VERSION "HSCAN1"

NS_ :

BS_:

BU_: BMS HVDCDC Gateway HCU Diagnostics Stability_Control_System Sensing_Diagnostic_Module vector__xxx

BO_ 663 BMS_HSC1_FrP02: 8 BMS
 SG_ BMSMainRelaySts_h1HSC1 : 54|2@0+ (1,0) [0|3] ""  HVDCDC

BO_ 667 BMS_HSC1_FrP07: 8 BMS
 SG_ BMSChrgrPlugCnctnIO_h1HSC1 : 6|1@0+ (1,0) [0|1] ""  Gateway
 SG_ BMSChrgStsIO_h1HSC1 : 7|1@0+ (1,0) [0|1] ""  Gateway

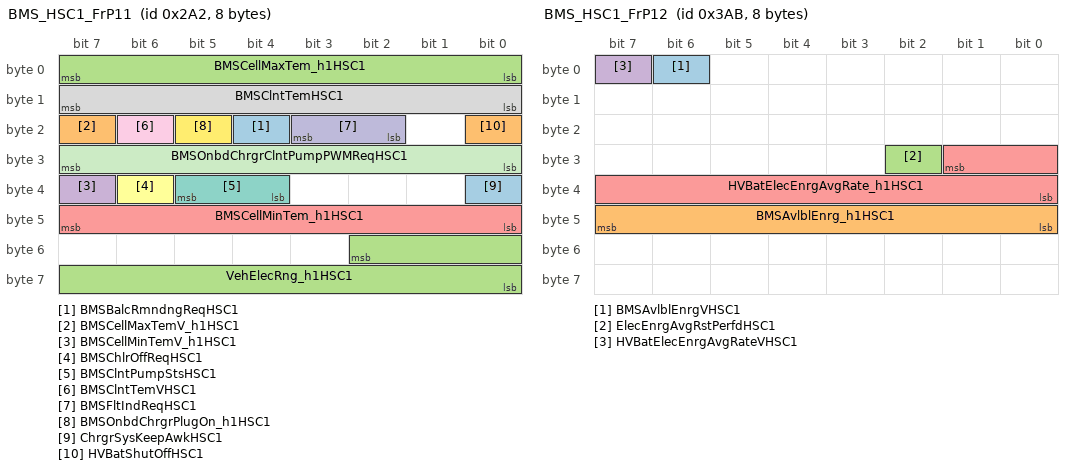
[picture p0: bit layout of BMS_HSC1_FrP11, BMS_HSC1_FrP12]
BO_ 674 BMS_HSC1_FrP11: 8 BMS
 SG_ BMSBalcRmndngReqHSC1 : 20|1@0+ (1,0) [0|1] ""  Gateway
 SG_ BMSCellMaxTemV_h1HSC1 : 23|1@0+ (1,0) [0|1] ""  Gateway,HCU
 SG_ BMSCellMaxTem_h1HSC1 : 7|8@0+ (0.5,-40) [-40|87.5] "DegC"  Gateway,HCU
 SG_ BMSCellMinTemV_h1HSC1 : 39|1@0+ (1,0) [0|1] ""  HCU
 SG_ BMSCellMinTem_h1HSC1 : 47|8@0+ (0.5,-40) [-40|87.5] "Deg C"  HCU
 SG_ BMSChlrOffReqHSC1 : 38|1@0+ (1,0) [0|1] ""  Gateway,HCU
 SG_ BMSClntPumpStsHSC1 : 37|2@0+ (1,0) [0|3] ""  Gateway
 SG_ BMSClntTemHSC1 : 15|8@0+ (0.5,-40) [-40|87.5] "degC"  Gateway,HCU
 SG_ BMSClntTemVHSC1 : 22|1@0+ (1,0) [0|1] ""  Gateway,HCU
 SG_ BMSFltIndReqHSC1 : 19|2@0+ (1,0) [0|3] ""  Gateway
 SG_ BMSOnbdChrgrClntPumpPWMReqHSC1 : 31|8@0+ (0.4,0) [0|102] "%"  HCU
 SG_ BMSOnbdChrgrPlugOn_h1HSC1 : 21|1@0+ (1,0) [0|1] ""  Gateway,HCU
 SG_ ChrgrSysKeepAwkHSC1 : 32|1@0+ (1,0) [0|1] ""  HVDCDC
 SG_ HVBatShutOffHSC1 : 16|1@0+ (1,0) [0|1] ""  Gateway
 SG_ VehElecRng_h1HSC1 : 50|11@0+ (1,0) [0|2047] "km"  Gateway

BO_ 939 BMS_HSC1_FrP12: 8 BMS
 SG_ BMSAvlblEnrgVHSC1 : 6|1@0+ (1,0) [0|1] ""  Gateway,HCU
 SG_ BMSAvlblEnrg_h1HSC1 : 47|8@0+ (0.1,0) [0|25.5] "kWh"  Gateway,HCU
 SG_ ElecEnrgAvgRstPerfdHSC1 : 26|1@0+ (1,0) [0|1] ""  Gateway
 SG_ HVBatElecEnrgAvgRateVHSC1 : 7|1@0+ (1,0) [0|1] ""  Gateway
 SG_ HVBatElecEnrgAvgRate_h1HSC1 : 25|10@0+ (0.1,-20) [-20|82.3] ""  Gateway

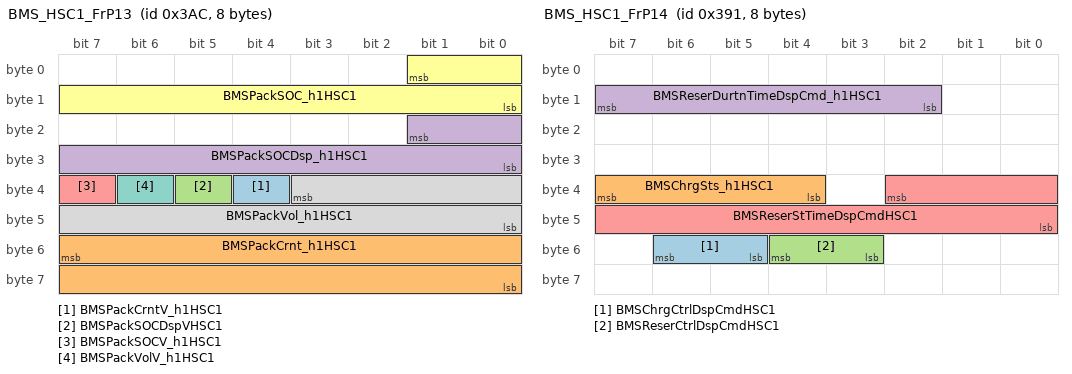
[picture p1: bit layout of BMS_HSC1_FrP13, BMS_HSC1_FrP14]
BO_ 940 BMS_HSC1_FrP13: 8 BMS
 SG_ BMSPackCrntV_h1HSC1 : 36|1@0+ (1,0) [0|1] ""  Gateway
 SG_ BMSPackCrnt_h1HSC1 : 55|16@0+ (0.025,-1000) [-1000|638.375] "A"  Gateway
 SG_ BMSPackSOCDspVHSC1 : 37|1@0+ (1,0) [0|1] ""  Gateway
 SG_ BMSPackSOCDsp_h1HSC1 : 17|10@0+ (0.1,0) [0|102.3] ""  Gateway
 SG_ BMSPackSOCV_h1HSC1 : 39|1@0+ (1,0) [0|1] ""  vector__xxx
 SG_ BMSPackSOC_h1HSC1 : 1|10@0+ (0.1,0) [0|102.3] "%"  vector__xxx
 SG_ BMSPackVolV_h1HSC1 : 38|1@0+ (1,0) [0|1] ""  HVDCDC,Gateway
 SG_ BMSPackVol_h1HSC1 : 35|12@0+ (0.25,0) [0|1023.75] "V"  HVDCDC,Gateway

BO_ 913 BMS_HSC1_FrP14: 8 BMS
 SG_ BMSChrgCtrlDspCmdHSC1 : 54|2@0+ (1,0) [0|3] ""  Gateway
 SG_ BMSChrgSts_h1HSC1 : 39|4@0+ (1,0) [0|15] ""  Gateway
 SG_ BMSReserCtrlDspCmdHSC1 : 52|2@0+ (1,0) [0|3] ""  Gateway
 SG_ BMSReserDurtnTimeDspCmd_h1HSC1 : 15|6@0+ (0.5,0) [0|20] ""  Gateway
 SG_ BMSReserStTimeDspCmdHSC1 : 34|11@0+ (1,0) [0|2047] ""  Gateway

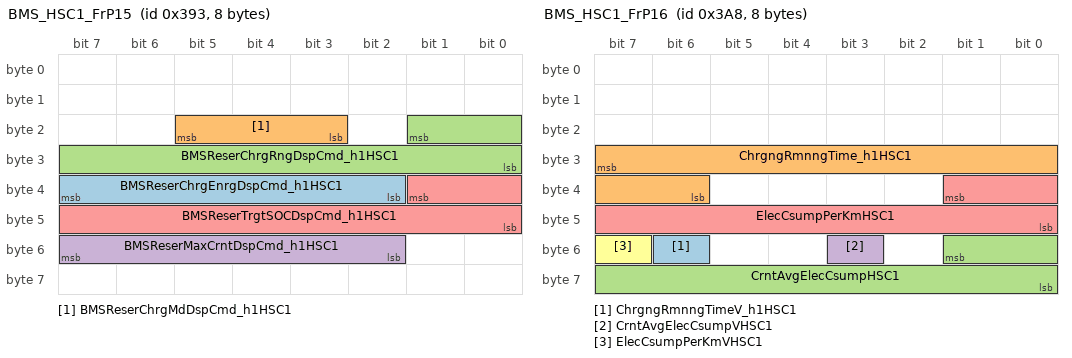
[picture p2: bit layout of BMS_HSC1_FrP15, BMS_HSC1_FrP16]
BO_ 915 BMS_HSC1_FrP15: 8 BMS
 SG_ BMSReserChrgEnrgDspCmd_h1HSC1 : 39|6@0+ (1,0) [0|63] ""  Gateway
 SG_ BMSReserChrgMdDspCmd_h1HSC1 : 21|3@0+ (1,0) [0|7] ""  Gateway
 SG_ BMSReserChrgRngDspCmd_h1HSC1 : 17|10@0+ (1,0) [0|1023] ""  Gateway
 SG_ BMSReserMaxCrntDspCmd_h1HSC1 : 55|6@0+ (1,0) [0|32] ""  Gateway
 SG_ BMSReserTrgtSOCDspCmd_h1HSC1 : 33|10@0+ (0.1,0) [0|102.3] ""  Gateway

BO_ 936 BMS_HSC1_FrP16: 8 BMS
 SG_ ChrgngRmnngTimeV_h1HSC1 : 54|1@0+ (1,0) [0|1] ""  Gateway
 SG_ ChrgngRmnngTime_h1HSC1 : 31|10@0+ (1,0) [0|1023] "minute"  Gateway
 SG_ CrntAvgElecCsumpHSC1 : 49|10@0+ (0.1,-20) [-20|82.3] "kwh/100km"  Gateway
 SG_ CrntAvgElecCsumpVHSC1 : 51|1@0+ (1,0) [0|1] ""  Gateway
 SG_ ElecCsumpPerKmHSC1 : 33|10@0+ (0.1,-20) [-20|82.3] "kwh/100km"  Gateway
 SG_ ElecCsumpPerKmVHSC1 : 55|1@0+ (1,0) [0|1] ""  Gateway

BO_ 1803 DIAG_DTCInfo_BMS: 7 BMS
 SG_ DTCInfomationBMSHSC1 : 7|56@0+ (1,0) [0|0] ""  Gateway

BO_ 1929 DIAG_PhysResp_BMS: 8 BMS
 SG_ DiagnosticRespBMS : 7|64@0+ (1,0) [0|0] ""  Diagnostics

BO_ 2015 DIAG_FuncReq_HSC1: 8 Diagnostics
 SG_ DiagnosticFuncAddrReq : 7|64@0+ (1,0) [0|0] ""  BMS

BO_ 1921 DIAG_PhysReq_BMS: 8 Diagnostics
 SG_ DiagnosticReqBMS : 7|64@0+ (1,0) [0|0] ""  BMS

BO_ 868 GW_HSC1_AC_FrP03: 8 Gateway
 SG_ ACComprReqHSC1 : 17|2@0+ (1,0) [0|3] ""  BMS
 SG_ HVBatCoolngSysEnbdHSC1 : 55|1@0+ (1,0) [0|1] ""  BMS

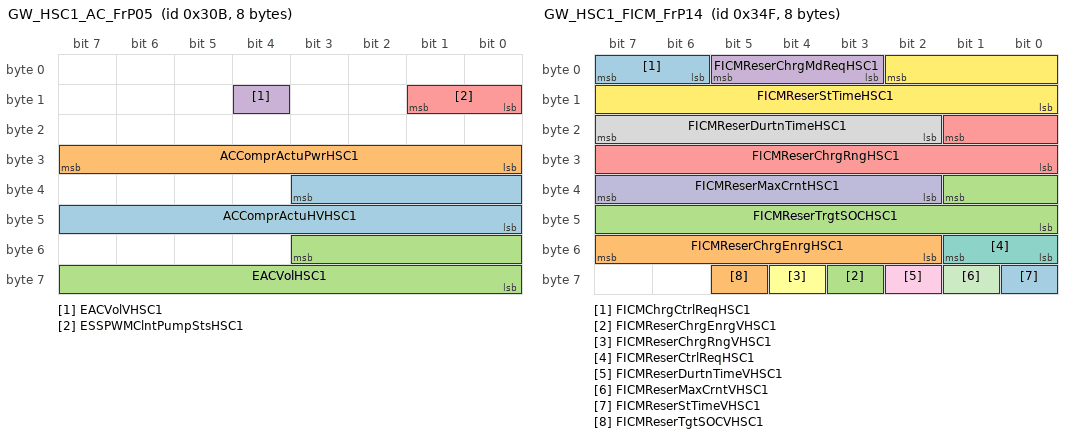
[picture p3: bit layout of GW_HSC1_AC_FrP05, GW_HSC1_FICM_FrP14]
BO_ 779 GW_HSC1_AC_FrP05: 8 Gateway
 SG_ ACComprActuHVHSC1 : 35|12@0+ (0.25,0) [0|1023.25] ""  BMS
 SG_ ACComprActuPwrHSC1 : 31|8@0+ (0.03,0) [0|7.65] "Kw"  BMS
 SG_ EACVolHSC1 : 51|12@0+ (0.25,0) [0|1023.75] ""  BMS
 SG_ EACVolVHSC1 : 12|1@0+ (1,0) [0|1] ""  BMS
 SG_ ESSPWMClntPumpStsHSC1 : 9|2@0+ (1,0) [0|3] ""  BMS

BO_ 883 GW_HSC1_AC_FrP06: 8 Gateway
 SG_ ACHtrPwrHSC1 : 15|8@0+ (0.03,0) [0|7.65] "Unit:KW"  BMS

BO_ 1130 GW_HSC1_BCM_FrP04: 8 Gateway
 SG_ VehLckngStaHSC1 : 22|3@0+ (1,0) [0|7] ""  BMS

BO_ 540 GW_HSC1_BCM_FrP06: 8 Gateway
 SG_ RVSReqHSC1 : 34|1@0+ (1,0) [0|1] ""  BMS

BO_ 498 GW_HSC1_BCM_FrP07: 2 Gateway
 SG_ SysBPMHSC1 : 5|2@0+ (1,0) [0|3] ""  BMS
 SG_ SysBPMEnbdHSC1 : 6|1@0+ (1,0) [0|1] ""  BMS

BO_ 886 GW_HSC1_FICM_FrP02: 8 Gateway
 SG_ RstrFctryDeftsReqHSC1 : 56|1@0+ (1,0) [0|1] ""  BMS

BO_ 847 GW_HSC1_FICM_FrP14: 8 Gateway
 SG_ FICMChrgCtrlReqHSC1 : 7|2@0+ (1,0) [0|3] ""  BMS
 SG_ FICMReserChrgEnrgHSC1 : 55|6@0+ (1,0) [0|63] ""  BMS
 SG_ FICMReserChrgEnrgVHSC1 : 59|1@0+ (1,0) [0|1] ""  BMS
 SG_ FICMReserChrgMdReqHSC1 : 5|3@0+ (1,0) [0|7] ""  BMS
 SG_ FICMReserChrgRngHSC1 : 17|10@0+ (1,0) [0|1023] ""  BMS
 SG_ FICMReserChrgRngVHSC1 : 60|1@0+ (1,0) [0|1] ""  BMS
 SG_ FICMReserCtrlReqHSC1 : 49|2@0+ (1,0) [0|3] ""  BMS
 SG_ FICMReserDurtnTimeHSC1 : 23|6@0+ (1,0) [0|63] ""  BMS
 SG_ FICMReserDurtnTimeVHSC1 : 58|1@0+ (1,0) [0|1] ""  BMS
 SG_ FICMReserMaxCrntHSC1 : 39|6@0+ (1,0) [0|32] ""  BMS
 SG_ FICMReserMaxCrntVHSC1 : 57|1@0+ (1,0) [0|1] ""  BMS
 SG_ FICMReserStTimeHSC1 : 2|11@0+ (1,0) [0|2047] ""  BMS
 SG_ FICMReserStTimeVHSC1 : 56|1@0+ (1,0) [0|1] ""  BMS
 SG_ FICMReserTgtSOCVHSC1 : 61|1@0+ (1,0) [0|1] ""  BMS
 SG_ FICMReserTrgtSOCHSC1 : 33|10@0+ (0.1,0) [0|102.3] ""  BMS

BO_ 361 GW_HSC1_FrP00: 6 Gateway
 SG_ BCMAvlbly_h1HSC1 : 31|1@0+ (1,0) [0|1] ""  BMS
 SG_ SCSAvlbly_h1HSC1 : 4|1@0+ (1,0) [0|1] ""  BMS

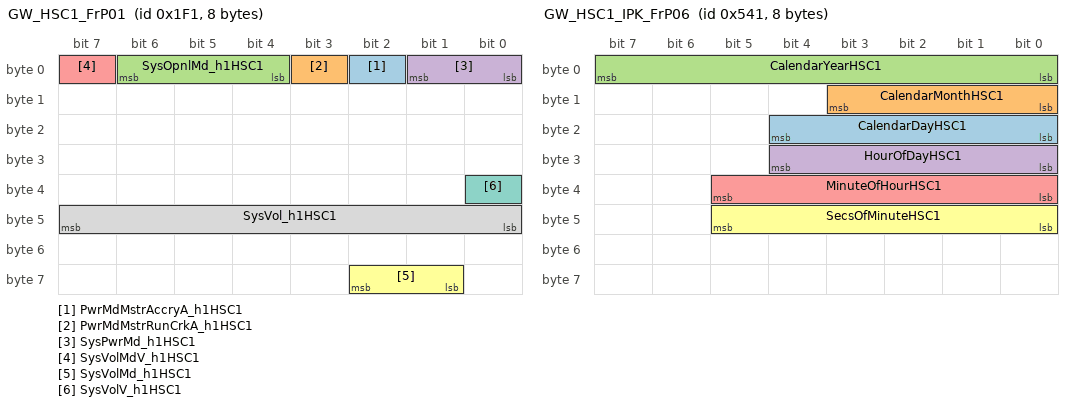
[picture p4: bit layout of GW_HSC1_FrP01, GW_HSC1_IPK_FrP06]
BO_ 497 GW_HSC1_FrP01: 8 Gateway
 SG_ PwrMdMstrAccryA_h1HSC1 : 2|1@0+ (1,0) [0|1] ""  BMS
 SG_ PwrMdMstrRunCrkA_h1HSC1 : 3|1@0+ (1,0) [0|1] ""  BMS
 SG_ SysOpnlMd_h1HSC1 : 6|3@0+ (1,0) [0|7] ""  BMS
 SG_ SysPwrMd_h1HSC1 : 1|2@0+ (1,0) [0|3] ""  BMS
 SG_ SysVolMdV_h1HSC1 : 7|1@0+ (1,0) [0|1] ""  BMS
 SG_ SysVolMd_h1HSC1 : 58|2@0+ (1,0) [0|3] ""  BMS
 SG_ SysVolV_h1HSC1 : 32|1@0+ (1,0) [0|1] ""  BMS
 SG_ SysVol_h1HSC1 : 47|8@0+ (0.1,3) [3|28.5] "V"  BMS

BO_ 1344 GW_HSC1_FrP07: 8 Gateway
 SG_ VehOdoV_h1HSC1 : 31|1@0+ (1,0) [0|1] ""  BMS
 SG_ VehOdo_h1HSC1 : 7|24@0+ (1,0) [0|16777200] ""  BMS

BO_ 1009 GW_HSC1_FrP10: 8 Gateway
 SG_ OtsdAirTemCrValV_h1HSC1 : 48|1@0+ (1,0) [0|1] ""  BMS
 SG_ OtsdAirTemCrVal_h1HSC1 : 63|8@0+ (0.5,-40) [-40|87.5] "deg C"  BMS

BO_ 1345 GW_HSC1_IPK_FrP06: 8 Gateway
 SG_ CalendarDayHSC1 : 20|5@0+ (1,0) [0|31] ""  BMS
 SG_ CalendarMonthHSC1 : 11|4@0+ (1,0) [0|15] ""  BMS
 SG_ CalendarYearHSC1 : 7|8@0+ (1,2000) [2000|2255] ""  BMS
 SG_ HourOfDayHSC1 : 28|5@0+ (1,0) [0|23] ""  BMS
 SG_ MinuteOfHourHSC1 : 37|6@0+ (1,0) [0|59] ""  BMS
 SG_ SecsOfMinuteHSC1 : 45|6@0+ (1,0) [0|59] ""  BMS

BO_ 835 GW_HSC1_IPK_FrP10: 8 Gateway
 SG_ ElecEnrgAvgRstReqHSC1 : 13|2@0+ (1,0) [0|3] ""  BMS

BO_ 175 HCU_HSC1_FrP00: 8 HCU
 SG_ EPTStCmdOnHSC1 : 17|1@0+ (1,0) [0|1] ""  BMS

BO_ 406 HCU_HSC1_FrP01: 8 HCU
 SG_ EPTRdyHSC1 : 38|1@0+ (1,0) [0|1] ""  BMS

BO_ 907 HCU_HSC1_FrP07: 8 HCU
 SG_ EPTEDUClntTemHSC1 : 47|8@0+ (1,-40) [-40|215] "DegC"  BMS
 SG_ EPTEDUClntTemVHSC1 : 13|1@0+ (1,0) [0|1] ""  BMS

BO_ 780 HCU_HSC1_FrP10: 8 HCU
 SG_ EPTEDUClntPumpStsHSC1 : 58|3@0+ (1,0) [0|7] ""  BMS

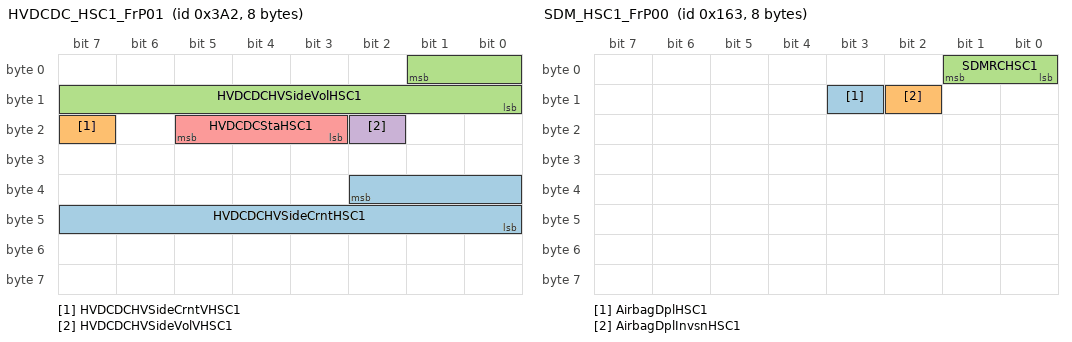
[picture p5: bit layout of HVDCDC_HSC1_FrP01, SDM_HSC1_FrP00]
BO_ 930 HVDCDC_HSC1_FrP01: 8 HVDCDC
 SG_ HVDCDCHVSideCrntHSC1 : 34|11@0+ (1,-1023) [-1023|1024] "A"  BMS
 SG_ HVDCDCHVSideCrntVHSC1 : 23|1@0+ (1,0) [0|1] ""  BMS
 SG_ HVDCDCHVSideVolHSC1 : 1|10@0+ (1,0) [0|1023] "V"  BMS
 SG_ HVDCDCHVSideVolVHSC1 : 18|1@0+ (1,0) [0|1] ""  BMS
 SG_ HVDCDCStaHSC1 : 21|3@0+ (1,0) [0|7] ""  BMS

BO_ 851 SCS_HSC1_FrP15: 8 Stability_Control_System
 SG_ VehSpdAvgDrvnV_h1HSC1 : 7|1@0+ (1,0) [0|1] ""  BMS
 SG_ VehSpdAvgDrvn_h1HSC1 : 6|15@0+ (0.015625,0) [0|511.984] "km/h"  BMS

BO_ 355 SDM_HSC1_FrP00: 8 Sensing_Diagnostic_Module
 SG_ AirbagDplHSC1 : 11|1@0+ (1,0) [0|1] ""  BMS
 SG_ AirbagDplInvsnHSC1 : 10|1@0+ (1,0) [0|1] ""  BMS
 SG_ SDMRCHSC1 : 1|2@0+ (1,0) [0|3] ""  BMS

CM_ SG_ 663 BMSMainRelaySts_h1HSC1 "Battery Management System Main Relay Status";
CM_ SG_ 667 BMSChrgrPlugCnctnIO_h1HSC1 "Battery Management System Charger Plug Connection Indication On";
CM_ SG_ 667 BMSChrgStsIO_h1HSC1 "Battery Management System Charge Status Indication On";
CM_ SG_ 674 BMSBalcRmndngReqHSC1 "Battery Management System Balance Reminding Request
";
CM_ SG_ 674 BMSCellMaxTemV_h1HSC1 "Battery Management System Cell Maximum Temperature Validity
";
CM_ SG_ 674 BMSCellMaxTem_h1HSC1 "Battery Management System Cell Maximum Temperature
";
CM_ SG_ 674 BMSCellMinTemV_h1HSC1 "Battery Management System Cell Minimum Temperature Validity";
CM_ SG_ 674 BMSCellMinTem_h1HSC1 "Battery Management System Cell Minimum Temperature";
CM_ SG_ 674 BMSChlrOffReqHSC1 "Battery Management System Chiller Off Request";
CM_ SG_ 674 BMSClntPumpStsHSC1 "Battery Management System Coolant Pump Status
";
CM_ SG_ 674 BMSClntTemHSC1 "Battery Management System Coolant Temperature";
CM_ SG_ 674 BMSClntTemVHSC1 "Battery Management System Coolant Temperature Validity";
CM_ SG_ 674 BMSFltIndReqHSC1 "Battery Management System Fault Indication Request
";
CM_ SG_ 674 BMSOnbdChrgrClntPumpPWMReqHSC1 "Battery Management System Onboard Charger Coolant Pump Pulse Width Modulation Request";
CM_ SG_ 674 BMSOnbdChrgrPlugOn_h1HSC1 "Battery Management System Onboard Charger Plug On";
CM_ SG_ 674 ChrgrSysKeepAwkHSC1 "Charger System Keep Awake";
CM_ SG_ 674 HVBatShutOffHSC1 "High Voltage Battery Shut Off";
CM_ SG_ 674 VehElecRng_h1HSC1 "Vehicle Electric Range";
CM_ SG_ 939 BMSAvlblEnrgVHSC1 "Battery Management System Available Energy Validity";
CM_ SG_ 939 BMSAvlblEnrg_h1HSC1 "Battery Management System Available Energy";
CM_ SG_ 939 ElecEnrgAvgRstPerfdHSC1 "Electric Energy Average Reset Performed";
CM_ SG_ 939 HVBatElecEnrgAvgRateVHSC1 "High Voltage Battery Electric Energy Average Rate Validity";
CM_ SG_ 939 HVBatElecEnrgAvgRate_h1HSC1 "High Voltage Battery Electric Energy Average Rate";
CM_ SG_ 940 BMSPackCrntV_h1HSC1 "Battery Management System Pack Current Validity";
CM_ SG_ 940 BMSPackCrnt_h1HSC1 "Battery Management System Pack Current";
CM_ SG_ 940 BMSPackSOCDspVHSC1 "Battery Management System Pack State Of Charge Display Validity";
CM_ SG_ 940 BMSPackSOCDsp_h1HSC1 "SOC displayed for customer";
CM_ SG_ 940 BMSPackSOCV_h1HSC1 "Battery Management System Pack State Of Charge Validity
";
CM_ SG_ 940 BMSPackSOC_h1HSC1 "Battery Management System Pack State Of Charge
";
CM_ SG_ 940 BMSPackVolV_h1HSC1 "Battery Management System Pack Voltage Validity";
CM_ SG_ 940 BMSPackVol_h1HSC1 "Battery Management System Pack Voltage";
CM_ SG_ 913 BMSChrgCtrlDspCmdHSC1 "Battery Management System Charge Control Display Command";
CM_ SG_ 913 BMSChrgSts_h1HSC1 "Battery Management System Charge Status";
CM_ SG_ 913 BMSReserCtrlDspCmdHSC1 "Battery Management System Reservation Control Display Command";
CM_ SG_ 913 BMSReserDurtnTimeDspCmd_h1HSC1 "Battery Management System Reservation Duration Time Display Command";
CM_ SG_ 913 BMSReserStTimeDspCmdHSC1 "Battery Management System Reservation Start Time Display Command";
CM_ SG_ 915 BMSReserChrgEnrgDspCmd_h1HSC1 "Battery Management System Reservation Charge Energy Display Command";
CM_ SG_ 915 BMSReserChrgMdDspCmd_h1HSC1 "Battery Management System Reservation Charge Mode Display Command";
CM_ SG_ 915 BMSReserChrgRngDspCmd_h1HSC1 "Battery Management System Reservation Charge Range Display Command";
CM_ SG_ 915 BMSReserMaxCrntDspCmd_h1HSC1 "Battery Management System Reservation Maximun Current Display Command";
CM_ SG_ 915 BMSReserTrgtSOCDspCmd_h1HSC1 "Battery Management System Reservaion Target Soc Display Command";
CM_ SG_ 936 ChrgngRmnngTimeV_h1HSC1 "Charging Remaining Time Validity";
CM_ SG_ 936 ChrgngRmnngTime_h1HSC1 "Charging Remaining Time";
CM_ SG_ 936 CrntAvgElecCsumpHSC1 "Current Average Electric Consumption";
CM_ SG_ 936 CrntAvgElecCsumpVHSC1 "Current Average Electric Consumption Validity";
CM_ SG_ 936 ElecCsumpPerKmHSC1 "Electric Consumption Per Kilometer";
CM_ SG_ 936 ElecCsumpPerKmVHSC1 "Electric Consumption Per Kilometer Validity";
CM_ SG_ 1803 DTCInfomationBMSHSC1 "DTC Infomation of BMS

The length of DTC information signal is 7 bytes.
Byte 0 is MSB (most significant byte), and Byte 6 is LSB (least significant byte).
For each byte, Bit 7 is msb (most significant bit), and Bit 0 is lsb (least significant bit).

Byte 0:
Bit (7-4): DTC Serious Level
Bit (3-0): Reserved

Byte 1:
Bit (7-0): Reserved

Byte 2:
Bit (7-0): DTCHighByte

Byte 3:
Bit (7-0): DTCLowByte

Byte 4:
Bit (7-0): DTCFailureTypeByte

Byte 5:
Bit 7: warningIndicatorRequested
Bit 6: testNotCompletedThisOperationCycle
Bit 5: testFailedSinceLastClear
Bit 4: testNotCompletedSinceLastClear
Bit 3: confirmedDTC
Bit 2: pendingDTC
Bit 1: testFailedThisOperationCycle
Bit 0: testFailed

Byte 6:
Bit (7-0): DTC Type

For more detail, please refer to SMTC 2 800 004.
";
CM_ SG_ 1929 DiagnosticRespBMS "Diagnostic response from BMS";
CM_ SG_ 2015 DiagnosticFuncAddrReq "Diagnostic functional address request";
CM_ SG_ 1921 DiagnosticReqBMS "Diagnostic request to BMS";
CM_ SG_ 868 ACComprReqHSC1 "Air Conditioning Compressor Request";
CM_ SG_ 868 HVBatCoolngSysEnbdHSC1 "High Voltage Battery Cooling System Enabled
";
CM_ SG_ 779 ACComprActuHVHSC1 "Air Conditioning Compressor Actual High Voltage
";
CM_ SG_ 779 ACComprActuPwrHSC1 "Air Conditioning Compressor Actual Power
";
CM_ SG_ 779 EACVolHSC1 "Electric Air Conditioning Compressor Voltage
";
CM_ SG_ 779 EACVolVHSC1 "Electric Air Conditioning Compressor Voltage Validity
";
CM_ SG_ 779 ESSPWMClntPumpStsHSC1 "Energy Storage System Pulse Width Modulation Coolant Pump Status";
CM_ SG_ 1130 VehLckngStaHSC1 "Vehicle Locking State";
CM_ SG_ 540 RVSReqHSC1 "Remote Vehicle Start Request";
CM_ SG_ 498 SysBPMHSC1 "System Backup Power Mode";
CM_ SG_ 498 SysBPMEnbdHSC1 "System Backup Power Mode Enabled";
CM_ SG_ 886 RstrFctryDeftsReqHSC1 "Restore Factory Defaults Request";
CM_ SG_ 847 FICMChrgCtrlReqHSC1 "Front Infotainment Control Module Charge Control Request";
CM_ SG_ 847 FICMReserChrgEnrgHSC1 "Front Infotainment Control Module Reservation Charge Energy";
CM_ SG_ 847 FICMReserChrgEnrgVHSC1 "Front Infotainment Control Module Reservation Charge Energy Validity";
CM_ SG_ 847 FICMReserChrgMdReqHSC1 "Front Infotainment Control Module Reservation Charge Mode Request";
CM_ SG_ 847 FICMReserChrgRngHSC1 "Front Infotainment Control Module Reservation Charge Range";
CM_ SG_ 847 FICMReserChrgRngVHSC1 "Front Infotainment Control Module Reservation Charge Range Validity";
CM_ SG_ 847 FICMReserCtrlReqHSC1 "Front Infotainment Control Module Reservation Control Request";
CM_ SG_ 847 FICMReserDurtnTimeHSC1 "Front Infotainment Control Module Reservation Duration Time";
CM_ SG_ 847 FICMReserDurtnTimeVHSC1 "Front Infotainment Control Module Reservation Duration Time Validity";
CM_ SG_ 847 FICMReserMaxCrntHSC1 "Front Infotainment Control Module Reservation Maximun Current Request";
CM_ SG_ 847 FICMReserMaxCrntVHSC1 "Front Infotainment Control Module Reservation Maximun Current Request Validity";
CM_ SG_ 847 FICMReserStTimeHSC1 "Front Infotainment Control Module Reservation Start Time";
CM_ SG_ 847 FICMReserStTimeVHSC1 "Front Infotainment Control Module Reservation Start Time Validity";
CM_ SG_ 847 FICMReserTgtSOCVHSC1 "Front Infotainment Control Module Reservation Target Soc Validity";
CM_ SG_ 847 FICMReserTrgtSOCHSC1 "Front Infotainment Control Module Reservation Target Soc";
CM_ SG_ 361 BCMAvlbly_h1HSC1 "BCM Available

Detect if specific ECU is available according to node missing strategy by gateway ECU.
";
CM_ SG_ 361 SCSAvlbly_h1HSC1 "SCS Available

Detect if specific ECU is available according to node missing strategy by gateway ECU.

";
CM_ SG_ 497 PwrMdMstrAccryA_h1HSC1 "Power Mode Master Accessory Terminal Status";
CM_ SG_ 497 PwrMdMstrRunCrkA_h1HSC1 "Power Mode Master Run Crank Terminal Status";
CM_ SG_ 497 SysOpnlMd_h1HSC1 "System Operational Mode";
CM_ SG_ 497 SysPwrMd_h1HSC1 "System Power Mode";
CM_ SG_ 497 SysVolMdV_h1HSC1 "System Voltage Mode Validity ";
CM_ SG_ 497 SysVolMd_h1HSC1 "System Voltage Mode ";
CM_ SG_ 497 SysVolV_h1HSC1 "Battery Voltage Validity";
CM_ SG_ 497 SysVol_h1HSC1 "Battery Voltage";
CM_ SG_ 1344 VehOdoV_h1HSC1 "Vehicle Odometer Validity";
CM_ SG_ 1344 VehOdo_h1HSC1 "Vehicle Odometer";
CM_ SG_ 1009 OtsdAirTemCrValV_h1HSC1 "Outside Air Temperature Corrected Value Validity";
CM_ SG_ 1009 OtsdAirTemCrVal_h1HSC1 "Outside Air Temperature Corrected Value";
CM_ SG_ 1345 CalendarDayHSC1 "current day info.";
CM_ SG_ 1345 CalendarMonthHSC1 "current month info.";
CM_ SG_ 1345 CalendarYearHSC1 "current year info";
CM_ SG_ 1345 HourOfDayHSC1 "Hour Of Day.
current Hour info.";
CM_ SG_ 1345 MinuteOfHourHSC1 "Minute Of Hour.
current Minute info.";
CM_ SG_ 1345 SecsOfMinuteHSC1 "Seconds Of Minute
current Second info.";
CM_ SG_ 835 ElecEnrgAvgRstReqHSC1 "Electric Energy Average Reset Request";
CM_ SG_ 175 EPTStCmdOnHSC1 "Electric Powertrain Start Command On";
CM_ SG_ 406 EPTRdyHSC1 "Electric Powertrain Ready";
CM_ SG_ 907 EPTEDUClntTemHSC1 "Electric Powertrain Electric Drive Unit Coolant Temperature
";
CM_ SG_ 907 EPTEDUClntTemVHSC1 "Electric Powertrain Electric Drive Unit Coolant Temperature Validity
";
CM_ SG_ 780 EPTEDUClntPumpStsHSC1 "Electric Powertrain Electric Drive Unit Coolant Pump StatusElectric Powertrain Electric Drive Unit Coolant Pump Status";
CM_ SG_ 930 HVDCDCHVSideCrntHSC1 "High Voltage Direct Current Direct Current High Voltage Side Current";
CM_ SG_ 930 HVDCDCHVSideVolHSC1 "High Voltage Direct Current Direct Current High Voltage Side Voltage";
CM_ SG_ 930 HVDCDCHVSideVolVHSC1 "High Voltage Direct Current Direct Current High Voltage Side Voltage Validity";
CM_ SG_ 930 HVDCDCStaHSC1 "High Voltage Direct Current Direct Current State";
CM_ SG_ 851 VehSpdAvgDrvnV_h1HSC1 "Vehicle Speed Average Driven Validity";
CM_ SG_ 851 VehSpdAvgDrvn_h1HSC1 "Vehicle Speed Average Driven";
CM_ SG_ 355 AirbagDplHSC1 "Airbag Deployed";
CM_ SG_ 355 AirbagDplInvsnHSC1 "Airbag Deployed Inversion";
CM_ SG_ 355 SDMRCHSC1 "Sensing Diagnostic Module Rolling Count
";
BA_DEF_  "BaudRate" FLOAT 1000 1000000;
BA_DEF_ BO_  "GenMsgSendType" ENUM  "cyclic","Spontaneous","cyclicIfActive","spontaneousWithDelay","Immediate";
BA_DEF_ BO_  "GenMsgCycleTime" FLOAT 0 300000;
BA_DEF_ BO_  "GenMsgDelayTime" FLOAT 0 300000;
BA_DEF_ SG_  "GenSigStartValue" INT -9.22337203685478E+018 1.84467440737096E+019;
BA_DEF_ SG_  "GenSigMaxAge" FLOAT 0 300000;
BA_DEF_ SG_  "GenSigPubLatency" INT 0 200;
BA_DEF_ SG_  "GenSigWriteInterval" INT 0 5000;
BA_DEF_DEF_  "BaudRate" 1000;
BA_DEF_DEF_  "GenMsgSendType" "";
BA_DEF_DEF_  "GenMsgCycleTime" 0;
BA_DEF_DEF_  "GenMsgDelayTime" 0;
BA_DEF_DEF_  "GenSigStartValue" 0;
BA_DEF_DEF_  "GenSigMaxAge" 0;
BA_DEF_DEF_  "GenSigPubLatency" 0;
BA_DEF_DEF_  "GenSigWriteInterval" 0;
BA_ "BaudRate" 500000;
BA_ "GenMsgSendType" BO_ 663 0;
BA_ "GenMsgCycleTime" BO_ 663 50;
BA_ "GenMsgSendType" BO_ 667 0;
BA_ "GenMsgCycleTime" BO_ 667 50;
BA_ "GenMsgSendType" BO_ 674 0;
BA_ "GenMsgCycleTime" BO_ 674 100;
BA_ "GenMsgSendType" BO_ 939 0;
BA_ "GenMsgCycleTime" BO_ 939 100;
BA_ "GenMsgSendType" BO_ 940 0;
BA_ "GenMsgCycleTime" BO_ 940 100;
BA_ "GenMsgSendType" BO_ 913 0;
BA_ "GenMsgCycleTime" BO_ 913 100;
BA_ "GenMsgSendType" BO_ 915 0;
BA_ "GenMsgCycleTime" BO_ 915 100;
BA_ "GenMsgSendType" BO_ 936 0;
BA_ "GenMsgCycleTime" BO_ 936 100;
BA_ "GenMsgSendType" BO_ 1803 1;
BA_ "GenMsgSendType" BO_ 1929 4;
BA_ "GenMsgSendType" BO_ 2015 4;
BA_ "GenMsgSendType" BO_ 1921 4;
BA_ "GenMsgSendType" BO_ 868 0;
BA_ "GenMsgCycleTime" BO_ 868 100;
BA_ "GenMsgSendType" BO_ 779 0;
BA_ "GenMsgCycleTime" BO_ 779 100;
BA_ "GenMsgSendType" BO_ 883 0;
BA_ "GenMsgCycleTime" BO_ 883 100;
BA_ "GenMsgSendType" BO_ 1130 0;
BA_ "GenMsgCycleTime" BO_ 1130 50;
BA_ "GenMsgSendType" BO_ 540 0;
BA_ "GenMsgCycleTime" BO_ 540 50;
BA_ "GenMsgSendType" BO_ 498 0;
BA_ "GenMsgCycleTime" BO_ 498 20;
BA_ "GenMsgSendType" BO_ 886 0;
BA_ "GenMsgCycleTime" BO_ 886 100;
BA_ "GenMsgSendType" BO_ 847 0;
BA_ "GenMsgCycleTime" BO_ 847 100;
BA_ "GenMsgSendType" BO_ 361 0;
BA_ "GenMsgCycleTime" BO_ 361 20;
BA_ "GenMsgSendType" BO_ 497 0;
BA_ "GenMsgCycleTime" BO_ 497 20;
BA_ "GenMsgSendType" BO_ 1344 0;
BA_ "GenMsgCycleTime" BO_ 1344 1000;
BA_ "GenMsgSendType" BO_ 1009 0;
BA_ "GenMsgCycleTime" BO_ 1009 250;
BA_ "GenMsgSendType" BO_ 1345 0;
BA_ "GenMsgCycleTime" BO_ 1345 200;
BA_ "GenMsgSendType" BO_ 835 0;
BA_ "GenMsgCycleTime" BO_ 835 100;
BA_ "GenMsgSendType" BO_ 175 0;
BA_ "GenMsgCycleTime" BO_ 175 10;
BA_ "GenMsgSendType" BO_ 406 0;
BA_ "GenMsgCycleTime" BO_ 406 20;
BA_ "GenMsgSendType" BO_ 907 0;
BA_ "GenMsgCycleTime" BO_ 907 100;
BA_ "GenMsgSendType" BO_ 780 0;
BA_ "GenMsgCycleTime" BO_ 780 100;
BA_ "GenMsgSendType" BO_ 930 0;
BA_ "GenMsgCycleTime" BO_ 930 100;
BA_ "GenMsgSendType" BO_ 851 0;
BA_ "GenMsgCycleTime" BO_ 851 100;
BA_ "GenMsgSendType" BO_ 355 0;
BA_ "GenMsgCycleTime" BO_ 355 20;
BA_ "GenSigPubLatency" SG_ 663 BMSMainRelaySts_h1HSC1 10;
BA_ "GenSigMaxAge" SG_ 663 BMSMainRelaySts_h1HSC1 500;
BA_ "GenSigPubLatency" SG_ 667 BMSChrgrPlugCnctnIO_h1HSC1 10;
BA_ "GenSigStartValue" SG_ 667 BMSChrgrPlugCnctnIO_h1HSC1 1;
BA_ "GenSigPubLatency" SG_ 667 BMSChrgStsIO_h1HSC1 10;
BA_ "GenSigStartValue" SG_ 667 BMSChrgStsIO_h1HSC1 1;
BA_ "GenSigPubLatency" SG_ 674 BMSBalcRmndngReqHSC1 10;
BA_ "GenSigPubLatency" SG_ 674 BMSCellMaxTemV_h1HSC1 10;
BA_ "GenSigStartValue" SG_ 674 BMSCellMaxTemV_h1HSC1 1;
BA_ "GenSigMaxAge" SG_ 674 BMSCellMaxTemV_h1HSC1 400;
BA_ "GenSigPubLatency" SG_ 674 BMSCellMaxTem_h1HSC1 10;
BA_ "GenSigStartValue" SG_ 674 BMSCellMaxTem_h1HSC1 255;
BA_ "GenSigMaxAge" SG_ 674 BMSCellMaxTem_h1HSC1 400;
BA_ "GenSigPubLatency" SG_ 674 BMSCellMinTemV_h1HSC1 10;
BA_ "GenSigStartValue" SG_ 674 BMSCellMinTemV_h1HSC1 1;
BA_ "GenSigMaxAge" SG_ 674 BMSCellMinTemV_h1HSC1 300;
BA_ "GenSigPubLatency" SG_ 674 BMSCellMinTem_h1HSC1 10;
BA_ "GenSigStartValue" SG_ 674 BMSCellMinTem_h1HSC1 255;
BA_ "GenSigMaxAge" SG_ 674 BMSCellMinTem_h1HSC1 300;
BA_ "GenSigPubLatency" SG_ 674 BMSChlrOffReqHSC1 10;
BA_ "GenSigMaxAge" SG_ 674 BMSChlrOffReqHSC1 300;
BA_ "GenSigPubLatency" SG_ 674 BMSClntPumpStsHSC1 10;
BA_ "GenSigPubLatency" SG_ 674 BMSClntTemHSC1 10;
BA_ "GenSigStartValue" SG_ 674 BMSClntTemHSC1 255;
BA_ "GenSigMaxAge" SG_ 674 BMSClntTemHSC1 300;
BA_ "GenSigPubLatency" SG_ 674 BMSClntTemVHSC1 10;
BA_ "GenSigStartValue" SG_ 674 BMSClntTemVHSC1 1;
BA_ "GenSigMaxAge" SG_ 674 BMSClntTemVHSC1 300;
BA_ "GenSigPubLatency" SG_ 674 BMSFltIndReqHSC1 10;
BA_ "GenSigPubLatency" SG_ 674 BMSOnbdChrgrClntPumpPWMReqHSC1 10;
BA_ "GenSigMaxAge" SG_ 674 BMSOnbdChrgrClntPumpPWMReqHSC1 400;
BA_ "GenSigPubLatency" SG_ 674 BMSOnbdChrgrPlugOn_h1HSC1 10;
BA_ "GenSigMaxAge" SG_ 674 BMSOnbdChrgrPlugOn_h1HSC1 300;
BA_ "GenSigPubLatency" SG_ 674 ChrgrSysKeepAwkHSC1 10;
BA_ "GenSigMaxAge" SG_ 674 ChrgrSysKeepAwkHSC1 500;
BA_ "GenSigPubLatency" SG_ 674 HVBatShutOffHSC1 10;
BA_ "GenSigStartValue" SG_ 674 HVBatShutOffHSC1 1;
BA_ "GenSigMaxAge" SG_ 674 HVBatShutOffHSC1 500;
BA_ "GenSigPubLatency" SG_ 674 VehElecRng_h1HSC1 10;
BA_ "GenSigStartValue" SG_ 674 VehElecRng_h1HSC1 2046;
BA_ "GenSigPubLatency" SG_ 939 BMSAvlblEnrgVHSC1 10;
BA_ "GenSigMaxAge" SG_ 939 BMSAvlblEnrgVHSC1 300;
BA_ "GenSigPubLatency" SG_ 939 BMSAvlblEnrg_h1HSC1 10;
BA_ "GenSigStartValue" SG_ 939 BMSAvlblEnrg_h1HSC1 255;
BA_ "GenSigMaxAge" SG_ 939 BMSAvlblEnrg_h1HSC1 300;
BA_ "GenSigPubLatency" SG_ 939 ElecEnrgAvgRstPerfdHSC1 10;
BA_ "GenSigPubLatency" SG_ 939 HVBatElecEnrgAvgRateVHSC1 10;
BA_ "GenSigStartValue" SG_ 939 HVBatElecEnrgAvgRateVHSC1 1;
BA_ "GenSigPubLatency" SG_ 939 HVBatElecEnrgAvgRate_h1HSC1 10;
BA_ "GenSigStartValue" SG_ 939 HVBatElecEnrgAvgRate_h1HSC1 1023;
BA_ "GenSigPubLatency" SG_ 940 BMSPackCrntV_h1HSC1 10;
BA_ "GenSigStartValue" SG_ 940 BMSPackCrntV_h1HSC1 1;
BA_ "GenSigPubLatency" SG_ 940 BMSPackCrnt_h1HSC1 10;
BA_ "GenSigStartValue" SG_ 940 BMSPackCrnt_h1HSC1 65535;
BA_ "GenSigPubLatency" SG_ 940 BMSPackSOCDspVHSC1 10;
BA_ "GenSigPubLatency" SG_ 940 BMSPackSOCDsp_h1HSC1 10;
BA_ "GenSigStartValue" SG_ 940 BMSPackSOCDsp_h1HSC1 1022;
BA_ "GenSigPubLatency" SG_ 940 BMSPackSOCV_h1HSC1 10;
BA_ "GenSigStartValue" SG_ 940 BMSPackSOCV_h1HSC1 1;
BA_ "GenSigPubLatency" SG_ 940 BMSPackSOC_h1HSC1 10;
BA_ "GenSigStartValue" SG_ 940 BMSPackSOC_h1HSC1 1023;
BA_ "GenSigPubLatency" SG_ 940 BMSPackVolV_h1HSC1 10;
BA_ "GenSigStartValue" SG_ 940 BMSPackVolV_h1HSC1 1;
BA_ "GenSigMaxAge" SG_ 940 BMSPackVolV_h1HSC1 500;
BA_ "GenSigPubLatency" SG_ 940 BMSPackVol_h1HSC1 10;
BA_ "GenSigStartValue" SG_ 940 BMSPackVol_h1HSC1 4095;
BA_ "GenSigMaxAge" SG_ 940 BMSPackVol_h1HSC1 500;
BA_ "GenSigPubLatency" SG_ 913 BMSChrgCtrlDspCmdHSC1 10;
BA_ "GenSigPubLatency" SG_ 913 BMSChrgSts_h1HSC1 20;
BA_ "GenSigPubLatency" SG_ 913 BMSReserCtrlDspCmdHSC1 10;
BA_ "GenSigPubLatency" SG_ 913 BMSReserDurtnTimeDspCmd_h1HSC1 20;
BA_ "GenSigStartValue" SG_ 913 BMSReserDurtnTimeDspCmd_h1HSC1 62;
BA_ "GenSigPubLatency" SG_ 913 BMSReserStTimeDspCmdHSC1 10;
BA_ "GenSigStartValue" SG_ 913 BMSReserStTimeDspCmdHSC1 2046;
BA_ "GenSigPubLatency" SG_ 915 BMSReserChrgEnrgDspCmd_h1HSC1 20;
BA_ "GenSigStartValue" SG_ 915 BMSReserChrgEnrgDspCmd_h1HSC1 62;
BA_ "GenSigPubLatency" SG_ 915 BMSReserChrgMdDspCmd_h1HSC1 20;
BA_ "GenSigPubLatency" SG_ 915 BMSReserChrgRngDspCmd_h1HSC1 20;
BA_ "GenSigStartValue" SG_ 915 BMSReserChrgRngDspCmd_h1HSC1 1022;
BA_ "GenSigPubLatency" SG_ 915 BMSReserMaxCrntDspCmd_h1HSC1 20;
BA_ "GenSigStartValue" SG_ 915 BMSReserMaxCrntDspCmd_h1HSC1 62;
BA_ "GenSigPubLatency" SG_ 915 BMSReserTrgtSOCDspCmd_h1HSC1 10;
BA_ "GenSigStartValue" SG_ 915 BMSReserTrgtSOCDspCmd_h1HSC1 1022;
BA_ "GenSigPubLatency" SG_ 936 ChrgngRmnngTimeV_h1HSC1 10;
BA_ "GenSigStartValue" SG_ 936 ChrgngRmnngTimeV_h1HSC1 1;
BA_ "GenSigPubLatency" SG_ 936 ChrgngRmnngTime_h1HSC1 10;
BA_ "GenSigStartValue" SG_ 936 ChrgngRmnngTime_h1HSC1 1023;
BA_ "GenSigPubLatency" SG_ 936 CrntAvgElecCsumpHSC1 10;
BA_ "GenSigStartValue" SG_ 936 CrntAvgElecCsumpHSC1 1023;
BA_ "GenSigPubLatency" SG_ 936 CrntAvgElecCsumpVHSC1 10;
BA_ "GenSigStartValue" SG_ 936 CrntAvgElecCsumpVHSC1 1;
BA_ "GenSigPubLatency" SG_ 936 ElecCsumpPerKmHSC1 10;
BA_ "GenSigStartValue" SG_ 936 ElecCsumpPerKmHSC1 1023;
BA_ "GenSigPubLatency" SG_ 936 ElecCsumpPerKmVHSC1 10;
BA_ "GenSigStartValue" SG_ 936 ElecCsumpPerKmVHSC1 1;
BA_ "GenSigPubLatency" SG_ 1803 DTCInfomationBMSHSC1 100;
BA_ "GenSigWriteInterval" SG_ 1803 DTCInfomationBMSHSC1 1000;
BA_ "GenSigPubLatency" SG_ 1929 DiagnosticRespBMS 10;
BA_ "GenSigWriteInterval" SG_ 1929 DiagnosticRespBMS 10;
BA_ "GenSigMaxAge" SG_ 1929 DiagnosticRespBMS 50;
BA_ "GenSigPubLatency" SG_ 2015 DiagnosticFuncAddrReq 5;
BA_ "GenSigWriteInterval" SG_ 2015 DiagnosticFuncAddrReq 10;
BA_ "GenSigMaxAge" SG_ 2015 DiagnosticFuncAddrReq 25;
BA_ "GenSigPubLatency" SG_ 1921 DiagnosticReqBMS 5;
BA_ "GenSigWriteInterval" SG_ 1921 DiagnosticReqBMS 10;
BA_ "GenSigMaxAge" SG_ 1921 DiagnosticReqBMS 25;
BA_ "GenSigMaxAge" SG_ 868 ACComprReqHSC1 300;
BA_ "GenSigMaxAge" SG_ 868 HVBatCoolngSysEnbdHSC1 300;
BA_ "GenSigMaxAge" SG_ 779 ACComprActuHVHSC1 300;
BA_ "GenSigMaxAge" SG_ 779 ACComprActuPwrHSC1 300;
BA_ "GenSigMaxAge" SG_ 779 EACVolHSC1 300;
BA_ "GenSigMaxAge" SG_ 779 EACVolVHSC1 300;
BA_ "GenSigMaxAge" SG_ 779 ESSPWMClntPumpStsHSC1 300;
BA_ "GenSigMaxAge" SG_ 883 ACHtrPwrHSC1 300;
BA_ "GenSigStartValue" SG_ 1130 VehLckngStaHSC1 7;
BA_ "GenSigMaxAge" SG_ 1130 VehLckngStaHSC1 250;
BA_ "GenSigMaxAge" SG_ 540 RVSReqHSC1 200;
BA_ "GenSigMaxAge" SG_ 498 SysBPMHSC1 100;
BA_ "GenSigMaxAge" SG_ 498 SysBPMEnbdHSC1 200;
BA_ "GenSigMaxAge" SG_ 886 RstrFctryDeftsReqHSC1 400;
BA_ "GenSigMaxAge" SG_ 847 FICMChrgCtrlReqHSC1 400;
BA_ "GenSigStartValue" SG_ 847 FICMReserChrgEnrgHSC1 63;
BA_ "GenSigMaxAge" SG_ 847 FICMReserChrgEnrgHSC1 400;
BA_ "GenSigStartValue" SG_ 847 FICMReserChrgEnrgVHSC1 1;
BA_ "GenSigMaxAge" SG_ 847 FICMReserChrgEnrgVHSC1 400;
BA_ "GenSigMaxAge" SG_ 847 FICMReserChrgMdReqHSC1 400;
BA_ "GenSigStartValue" SG_ 847 FICMReserChrgRngHSC1 1023;
BA_ "GenSigMaxAge" SG_ 847 FICMReserChrgRngHSC1 400;
BA_ "GenSigStartValue" SG_ 847 FICMReserChrgRngVHSC1 1;
BA_ "GenSigMaxAge" SG_ 847 FICMReserChrgRngVHSC1 400;
BA_ "GenSigMaxAge" SG_ 847 FICMReserCtrlReqHSC1 400;
BA_ "GenSigStartValue" SG_ 847 FICMReserDurtnTimeHSC1 63;
BA_ "GenSigMaxAge" SG_ 847 FICMReserDurtnTimeHSC1 400;
BA_ "GenSigStartValue" SG_ 847 FICMReserDurtnTimeVHSC1 1;
BA_ "GenSigMaxAge" SG_ 847 FICMReserDurtnTimeVHSC1 400;
BA_ "GenSigStartValue" SG_ 847 FICMReserMaxCrntHSC1 63;
BA_ "GenSigMaxAge" SG_ 847 FICMReserMaxCrntHSC1 400;
BA_ "GenSigStartValue" SG_ 847 FICMReserMaxCrntVHSC1 1;
BA_ "GenSigMaxAge" SG_ 847 FICMReserMaxCrntVHSC1 400;
BA_ "GenSigStartValue" SG_ 847 FICMReserStTimeHSC1 2047;
BA_ "GenSigMaxAge" SG_ 847 FICMReserStTimeHSC1 400;
BA_ "GenSigStartValue" SG_ 847 FICMReserStTimeVHSC1 1;
BA_ "GenSigMaxAge" SG_ 847 FICMReserStTimeVHSC1 400;
BA_ "GenSigStartValue" SG_ 847 FICMReserTgtSOCVHSC1 1;
BA_ "GenSigMaxAge" SG_ 847 FICMReserTgtSOCVHSC1 400;
BA_ "GenSigStartValue" SG_ 847 FICMReserTrgtSOCHSC1 1023;
BA_ "GenSigMaxAge" SG_ 847 FICMReserTrgtSOCHSC1 400;
BA_ "GenSigPubLatency" SG_ 361 BCMAvlbly_h1HSC1 20;
BA_ "GenSigMaxAge" SG_ 361 BCMAvlbly_h1HSC1 100;
BA_ "GenSigPubLatency" SG_ 361 SCSAvlbly_h1HSC1 20;
BA_ "GenSigMaxAge" SG_ 361 SCSAvlbly_h1HSC1 100;
BA_ "GenSigPubLatency" SG_ 497 PwrMdMstrAccryA_h1HSC1 20;
BA_ "GenSigMaxAge" SG_ 497 PwrMdMstrAccryA_h1HSC1 100;
BA_ "GenSigPubLatency" SG_ 497 PwrMdMstrRunCrkA_h1HSC1 20;
BA_ "GenSigMaxAge" SG_ 497 PwrMdMstrRunCrkA_h1HSC1 100;
BA_ "GenSigPubLatency" SG_ 497 SysOpnlMd_h1HSC1 100;
BA_ "GenSigMaxAge" SG_ 497 SysOpnlMd_h1HSC1 300;
BA_ "GenSigPubLatency" SG_ 497 SysPwrMd_h1HSC1 20;
BA_ "GenSigMaxAge" SG_ 497 SysPwrMd_h1HSC1 100;
BA_ "GenSigPubLatency" SG_ 497 SysVolMdV_h1HSC1 100;
BA_ "GenSigMaxAge" SG_ 497 SysVolMdV_h1HSC1 300;
BA_ "GenSigPubLatency" SG_ 497 SysVolMd_h1HSC1 100;
BA_ "GenSigMaxAge" SG_ 497 SysVolMd_h1HSC1 300;
BA_ "GenSigPubLatency" SG_ 497 SysVolV_h1HSC1 100;
BA_ "GenSigMaxAge" SG_ 497 SysVolV_h1HSC1 300;
BA_ "GenSigPubLatency" SG_ 497 SysVol_h1HSC1 100;
BA_ "GenSigMaxAge" SG_ 497 SysVol_h1HSC1 300;
BA_ "GenSigPubLatency" SG_ 1344 VehOdoV_h1HSC1 500;
BA_ "GenSigMaxAge" SG_ 1344 VehOdoV_h1HSC1 300;
BA_ "GenSigPubLatency" SG_ 1344 VehOdo_h1HSC1 500;
BA_ "GenSigMaxAge" SG_ 1344 VehOdo_h1HSC1 300;
BA_ "GenSigPubLatency" SG_ 1009 OtsdAirTemCrValV_h1HSC1 250;
BA_ "GenSigMaxAge" SG_ 1009 OtsdAirTemCrValV_h1HSC1 300;
BA_ "GenSigPubLatency" SG_ 1009 OtsdAirTemCrVal_h1HSC1 250;
BA_ "GenSigMaxAge" SG_ 1009 OtsdAirTemCrVal_h1HSC1 300;
BA_ "GenSigMaxAge" SG_ 1345 CalendarDayHSC1 300;
BA_ "GenSigMaxAge" SG_ 1345 CalendarMonthHSC1 300;
BA_ "GenSigMaxAge" SG_ 1345 CalendarYearHSC1 300;
BA_ "GenSigMaxAge" SG_ 1345 HourOfDayHSC1 300;
BA_ "GenSigMaxAge" SG_ 1345 MinuteOfHourHSC1 300;
BA_ "GenSigMaxAge" SG_ 1345 SecsOfMinuteHSC1 300;
BA_ "GenSigMaxAge" SG_ 835 ElecEnrgAvgRstReqHSC1 300;
BA_ "GenSigPubLatency" SG_ 175 EPTStCmdOnHSC1 10;
BA_ "GenSigMaxAge" SG_ 175 EPTStCmdOnHSC1 50;
BA_ "GenSigPubLatency" SG_ 406 EPTRdyHSC1 10;
BA_ "GenSigMaxAge" SG_ 406 EPTRdyHSC1 100;
BA_ "GenSigPubLatency" SG_ 907 EPTEDUClntTemHSC1 10;
BA_ "GenSigStartValue" SG_ 907 EPTEDUClntTemHSC1 254;
BA_ "GenSigMaxAge" SG_ 907 EPTEDUClntTemHSC1 100;
BA_ "GenSigPubLatency" SG_ 907 EPTEDUClntTemVHSC1 10;
BA_ "GenSigMaxAge" SG_ 907 EPTEDUClntTemVHSC1 100;
BA_ "GenSigPubLatency" SG_ 780 EPTEDUClntPumpStsHSC1 10;
BA_ "GenSigMaxAge" SG_ 780 EPTEDUClntPumpStsHSC1 300;
BA_ "GenSigPubLatency" SG_ 930 HVDCDCHVSideCrntHSC1 10;
BA_ "GenSigMaxAge" SG_ 930 HVDCDCHVSideCrntHSC1 300;
BA_ "GenSigPubLatency" SG_ 930 HVDCDCHVSideCrntVHSC1 10;
BA_ "GenSigStartValue" SG_ 930 HVDCDCHVSideCrntVHSC1 1;
BA_ "GenSigMaxAge" SG_ 930 HVDCDCHVSideCrntVHSC1 50;
BA_ "GenSigPubLatency" SG_ 930 HVDCDCHVSideVolHSC1 10;
BA_ "GenSigMaxAge" SG_ 930 HVDCDCHVSideVolHSC1 100;
BA_ "GenSigPubLatency" SG_ 930 HVDCDCHVSideVolVHSC1 10;
BA_ "GenSigStartValue" SG_ 930 HVDCDCHVSideVolVHSC1 1;
BA_ "GenSigMaxAge" SG_ 930 HVDCDCHVSideVolVHSC1 100;
BA_ "GenSigPubLatency" SG_ 930 HVDCDCStaHSC1 10;
BA_ "GenSigMaxAge" SG_ 930 HVDCDCStaHSC1 50;
BA_ "GenSigPubLatency" SG_ 851 VehSpdAvgDrvnV_h1HSC1 10;
BA_ "GenSigMaxAge" SG_ 851 VehSpdAvgDrvnV_h1HSC1 50;
BA_ "GenSigPubLatency" SG_ 851 VehSpdAvgDrvn_h1HSC1 10;
BA_ "GenSigMaxAge" SG_ 851 VehSpdAvgDrvn_h1HSC1 50;
BA_ "GenSigPubLatency" SG_ 355 AirbagDplHSC1 10;
BA_ "GenSigMaxAge" SG_ 355 AirbagDplHSC1 50;
BA_ "GenSigPubLatency" SG_ 355 AirbagDplInvsnHSC1 10;
BA_ "GenSigStartValue" SG_ 355 AirbagDplInvsnHSC1 1;
BA_ "GenSigMaxAge" SG_ 355 AirbagDplInvsnHSC1 250;
BA_ "GenSigPubLatency" SG_ 355 SDMRCHSC1 10;
BA_ "GenSigMaxAge" SG_ 355 SDMRCHSC1 250;
VAL_ 663 BMSMainRelaySts_h1HSC1 3 "Failure" 2 "Partly Closed" 1 "All Closed" 0 "All Open" ;
VAL_ 667 BMSChrgrPlugCnctnIO_h1HSC1 1 "Lamp Off" 0 "Lamp On" ;
VAL_ 667 BMSChrgStsIO_h1HSC1 1 "Lamp Off" 0 "Lamp On" ;
VAL_ 674 BMSBalcRmndngReqHSC1 1 "TRUE" 0 "FALSE" ;
VAL_ 674 BMSCellMaxTemV_h1HSC1 1 "Invalid" 0 "Valid" ;
VAL_ 674 BMSCellMinTemV_h1HSC1 1 "Invalid" 0 "Valid" ;
VAL_ 674 BMSChlrOffReqHSC1 1 "TRUE" 0 "FALSE" ;
VAL_ 674 BMSClntPumpStsHSC1 3 "Failed High" 2 "Failed Low" 1 "On" 0 "OFF" ;
VAL_ 674 BMSClntTemVHSC1 1 "Invalid" 0 "Valid" ;
VAL_ 674 BMSFltIndReqHSC1 2 "Flashing  Hertz Indication" 1 "Continuous Indication" 0 "No Indication" ;
VAL_ 674 BMSOnbdChrgrPlugOn_h1HSC1 1 "TRUE" 0 "FALSE" ;
VAL_ 674 ChrgrSysKeepAwkHSC1 1 "TRUE" 0 "FALSE" ;
VAL_ 674 HVBatShutOffHSC1 1 "TRUE" 0 "FALSE" ;
VAL_ 939 BMSAvlblEnrgVHSC1 1 "Invalid" 0 "Valid" ;
VAL_ 939 ElecEnrgAvgRstPerfdHSC1 1 "TRUE" 0 "FALSE" ;
VAL_ 939 HVBatElecEnrgAvgRateVHSC1 1 "Invalid" 0 "Valid" ;
VAL_ 940 BMSPackCrntV_h1HSC1 1 "Invalid" 0 "Valid" ;
VAL_ 940 BMSPackSOCDspVHSC1 1 "Invalid" 0 "Valid" ;
VAL_ 940 BMSPackSOCV_h1HSC1 1 "Invalid" 0 "Valid" ;
VAL_ 940 BMSPackVolV_h1HSC1 1 "Invalid" 0 "Valid" ;
VAL_ 913 BMSChrgCtrlDspCmdHSC1 3 "Reserved" 2 "Stop Charge" 1 "Start Charge" 0 "No Request" ;
VAL_ 913 BMSChrgSts_h1HSC1 5 "Reserved" 4 "Charge Fault" 3 "Balancing" 2 "Charge Done" 1 "Charging" 0 "None" ;
VAL_ 913 BMSReserCtrlDspCmdHSC1 3 "Reserved" 2 "Reservation Switch Off" 1 "Reservation Switch On" 0 "No Request" ;
VAL_ 915 BMSReserChrgMdDspCmd_h1HSC1 4 "Soc Based Mode" 3 "Range Based Mode" 2 "Energy Based Mode" 1 "Time Based Mode" 0 "Unavailable" ;
VAL_ 936 ChrgngRmnngTimeV_h1HSC1 1 "Invalid" 0 "Valid" ;
VAL_ 936 CrntAvgElecCsumpVHSC1 1 "Invalid" 0 "Valid" ;
VAL_ 936 ElecCsumpPerKmVHSC1 1 "Invalid" 0 "Valid" ;
VAL_ 868 ACComprReqHSC1 3 "reserved" 2 "Engage" 1 "disengage" 0 "disengage immediately" ;
VAL_ 868 HVBatCoolngSysEnbdHSC1 1 "TRUE" 0 "FALSE" ;
VAL_ 779 ACComprActuHVHSC1 4095 "Error" 4094 "Init" ;
VAL_ 779 EACVolVHSC1 1 "Invalid" 0 "Valid" ;
VAL_ 779 ESSPWMClntPumpStsHSC1 3 "Pump failure" 2 "Pump permanent on due to some kind of failure" 1 "Normal On" 0 "Nomarl Off" ;
VAL_ 1130 VehLckngStaHSC1 7 "Unknow" 6 "Reserved" 5 "Reserved" 4 "Super locked" 3 "Exterior Locked" 2 "Interior Locked" 1 "Signal Position Entry Unlocked" 0 "Unlocked" ;
VAL_ 540 RVSReqHSC1 1 "request" 0 "no request" ;
VAL_ 498 SysBPMHSC1 3 "Crank" 2 "Run" 1 "ACC" 0 "Off" ;
VAL_ 498 SysBPMEnbdHSC1 1 "TRUE" 0 "FALSE" ;
VAL_ 886 RstrFctryDeftsReqHSC1 1 "TRUE" 0 "FALSE" ;
VAL_ 847 FICMChrgCtrlReqHSC1 3 "Reserved" 2 "Stop Charge" 1 "Start Charge" 0 "No Request" ;
VAL_ 847 FICMReserChrgEnrgVHSC1 1 "Invalid" 0 "Valid" ;
VAL_ 847 FICMReserChrgMdReqHSC1 4 "Soc Based Mode" 3 "Range Based Mode" 2 "Energy Based Mode" 1 "Time Based Mode" 0 "No Request" ;
VAL_ 847 FICMReserChrgRngVHSC1 1 "Invalid" 0 "Valid" ;
VAL_ 847 FICMReserCtrlReqHSC1 3 "Reserved" 2 "Reservation Switch Off" 1 "Reservation Switch On" 0 "No Request" ;
VAL_ 847 FICMReserDurtnTimeVHSC1 1 "Invalid" 0 "Valid" ;
VAL_ 847 FICMReserMaxCrntVHSC1 1 "Invalid" 0 "Valid" ;
VAL_ 847 FICMReserStTimeVHSC1 1 "Invalid" 0 "Valid" ;
VAL_ 847 FICMReserTgtSOCVHSC1 1 "Invalid" 0 "Valid" ;
VAL_ 361 BCMAvlbly_h1HSC1 1 "TRUE" 0 "FALSE" ;
VAL_ 361 SCSAvlbly_h1HSC1 1 "TRUE" 0 "FALSE" ;
VAL_ 497 PwrMdMstrAccryA_h1HSC1 1 "Active" 0 "Inactive" ;
VAL_ 497 PwrMdMstrRunCrkA_h1HSC1 1 "Active" 0 "Inactive" ;
VAL_ 497 SysOpnlMd_h1HSC1 5 "Diagnosic or Reprogramming(Reserve)" 4 "Storage" 3 "Show Room(Reserve)" 2 "End of Line(Reserve)" 1 "Assembly" 0 "Normal Mode" ;
VAL_ 497 SysPwrMd_h1HSC1 3 "Crank" 2 "Run" 1 "ACC" 0 "Off" ;
VAL_ 497 SysVolMdV_h1HSC1 1 "Invalid" 0 "Valid" ;
VAL_ 497 SysVolMd_h1HSC1 3 "Illegal System  Voltage" 2 "High System Voltage" 1 "Low System Voltage" 0 "Normal" ;
VAL_ 497 SysVolV_h1HSC1 1 "Invalid" 0 "Valid" ;
VAL_ 1344 VehOdoV_h1HSC1 1 "Invalid" 0 "Valid" ;
VAL_ 1009 OtsdAirTemCrValV_h1HSC1 1 "Invalid" 0 "Valid" ;
VAL_ 1345 CalendarMonthHSC1 15 "Reserved" 14 "Reserved" 13 "Reserved" 12 "December" 11 "November" 10 "October" 9 "September" 8 "August" 7 "July" 6 "June" 5 "May" 4 "April" 3 "March" 2 "February" 1 "January" 0 "Unknown" ;
VAL_ 835 ElecEnrgAvgRstReqHSC1 1 "TRUE" 0 "FALSE" ;
VAL_ 175 EPTStCmdOnHSC1 1 "TRUE" 0 "FALSE" ;
VAL_ 406 EPTRdyHSC1 1 "ready" 0 "not ready" ;
VAL_ 907 EPTEDUClntTemVHSC1 1 "Invalid" 0 "Valid" ;
VAL_ 780 EPTEDUClntPumpStsHSC1 7 "All pump speed limited" 6 "One pump speed limited" 5 "One pump constant off because of fault" 4 "One pump constant on because of fault" 3 "All pump constant off because of fault" 2 "All pump constant on because of fault" 1 "Normal on" 0 "Normal off" ;
VAL_ 930 HVDCDCHVSideCrntVHSC1 1 "Invalid" 0 "Valid" ;
VAL_ 930 HVDCDCHVSideVolVHSC1 1 "Invalid" 0 "Valid" ;
VAL_ 930 HVDCDCStaHSC1 7 "Reserved" 6 "Reserved" 5 "Failure" 4 "Boost" 3 "DC Link Discharge" 2 "Buck" 1 "Reserved" 0 "Standby" ;
VAL_ 851 VehSpdAvgDrvnV_h1HSC1 1 "Invalid" 0 "Valid" ;
VAL_ 355 AirbagDplHSC1 1 "TRUE" 0 "FALSE" ;
VAL_ 355 AirbagDplInvsnHSC1 1 "No Airbag Deployed" 0 "Airbag Deployed" ;
